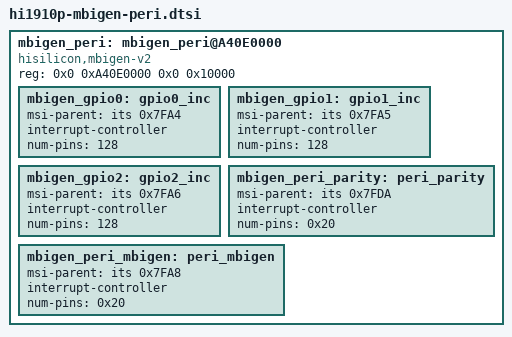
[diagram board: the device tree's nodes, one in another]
/**
* dts file for Hisilicon Ascend Dxxx Development Board
*
* Copyright (C) 2020 Hisilicon Ltd.
*
* This program is free software; you can redistribute it and/or modify
* it under the terms of the GNU General Public License version 2 as
* publishhed by the Free Software Foundation.
*
* Owner：OS
* Author:  c00283067
* Create: Tue Apr 21 20:07:41 EDT 2020
*/
    mbigen_peri: mbigen_peri@A40E0000 {
        compatible = "hisilicon,mbigen-v2";
        reg = <0x0 0xA40E0000 0x0 0x10000>;
        mbigen_gpio0: gpio0_inc {
            msi-parent = <&its 0x7FA4>;
            interrupt-controller;
            #interrupt-cells = <0x2>;
            num-pins = <128>;
        };
        mbigen_gpio1: gpio1_inc {
            msi-parent = <&its 0x7FA5>;
            interrupt-controller;
            #interrupt-cells = <0x2>;
            num-pins = <128>;
        };
        mbigen_gpio2: gpio2_inc {
            msi-parent = <&its 0x7FA6>;
            interrupt-controller;
            #interrupt-cells = <0x2>;
            num-pins = <128>;
        };
        mbigen_peri_parity: peri_parity {
            msi-parent = <&its 0x7FDA>;
            interrupt-controller;
            #interrupt-cells = <0x2>;
            num-pins = <0x20>;
        };
		mbigen_peri_mbigen: peri_mbigen {
            msi-parent = <&its 0x7FA8>;
            interrupt-controller;
            #interrupt-cells = <0x2>;
            num-pins = <0x20>;
        };
    };
